# BL702 register map
Vendor: Bouffalo Lab; Series: WiFi BT; File version: 1.0
Registers are 32-bit, read-write, reset 0x0 unless marked. A register's access mark holds for its fields unless they carry their own. Offsets are from the block's base; [hi:lo] are bit positions; {n}, {i} and the like mark numbered series.

## CAM
Base 0x4000AD00
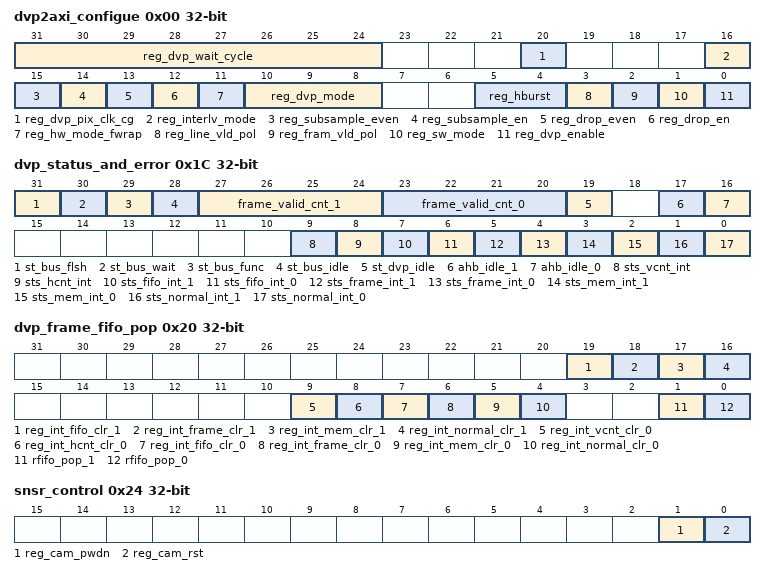
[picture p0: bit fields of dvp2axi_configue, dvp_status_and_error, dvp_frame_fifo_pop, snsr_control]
0x00 dvp2axi_configue
  [31:24] reg_dvp_wait_cycle, [20] reg_dvp_pix_clk_cg, [16] reg_interlv_mode, [15] reg_subsample_even, [14] reg_subsample_en, [13] reg_drop_even, [12] reg_drop_en, [11] reg_hw_mode_fwrap, [10:8] reg_dvp_mode, [5:4] reg_hburst, [3] reg_line_vld_pol, [2] reg_fram_vld_pol, [1] reg_sw_mode, [0] reg_dvp_enable
0x04 dvp2ahb_addr_start_0
  [31:0] reg_addr_start_0
0x08 dvp2ahb_mem_bcnt_0
  [31:0] reg_mem_burst_cnt_0
0x0C dvp2ahb_frame_bcnt_0
  [31:0] reg_frame_burst_cnt_0
0x10 dvp2ahb_addr_start_1
  [31:0] reg_addr_start_1
0x14 dvp2ahb_mem_bcnt_1
  [31:0] reg_mem_burst_cnt_1
0x18 dvp2ahb_frame_bcnt_1
  [31:0] reg_frame_burst_cnt_1
0x1C dvp_status_and_error
  [31] st_bus_flsh, [30] st_bus_wait, [29] st_bus_func, [28] st_bus_idle, [27:24] frame_valid_cnt_1, [23:20] frame_valid_cnt_0, [19] st_dvp_idle, [17] ahb_idle_1, [16] ahb_idle_0, [9] sts_vcnt_int, [8] sts_hcnt_int, [7] sts_fifo_int_1, [6] sts_fifo_int_0, [5] sts_frame_int_1, [4] sts_frame_int_0, [3] sts_mem_int_1, [2] sts_mem_int_0, [1] sts_normal_int_1, [0] sts_normal_int_0
0x20 dvp_frame_fifo_pop
  [19] reg_int_fifo_clr_1, [18] reg_int_frame_clr_1, [17] reg_int_mem_clr_1, [16] reg_int_normal_clr_1, [9] reg_int_vcnt_clr_0, [8] reg_int_hcnt_clr_0, [7] reg_int_fifo_clr_0, [6] reg_int_frame_clr_0, [5] reg_int_mem_clr_0, [4] reg_int_normal_clr_0, [1] rfifo_pop_1, [0] rfifo_pop_0
0x24 snsr_control
  [1] reg_cam_pwdn, [0] reg_cam_rst
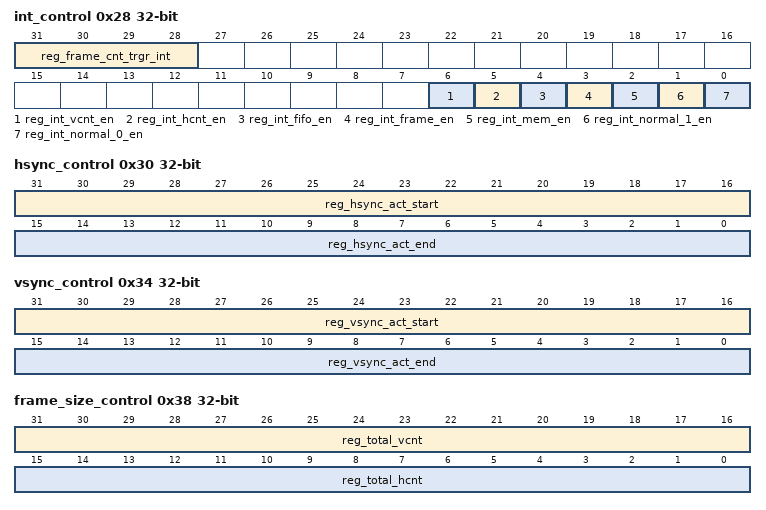
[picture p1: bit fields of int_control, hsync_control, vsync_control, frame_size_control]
0x28 int_control
  [31:28] reg_frame_cnt_trgr_int, [6] reg_int_vcnt_en, [5] reg_int_hcnt_en, [4] reg_int_fifo_en, [3] reg_int_frame_en, [2] reg_int_mem_en, [1] reg_int_normal_1_en, [0] reg_int_normal_0_en
0x30 hsync_control
  [31:16] reg_hsync_act_start, [15:0] reg_hsync_act_end
0x34 vsync_control
  [31:16] reg_vsync_act_start, [15:0] reg_vsync_act_end
0x38 frame_size_control
  [31:16] reg_total_vcnt, [15:0] reg_total_hcnt
{0x40+8i} frame_start_addr0_{i} (i=0..7)
  [31:0] frame_start_addr_0_{i}
{0x44+8i} frame_byte_cnt0_{i} (i=0..7)
  [31:0] frame_byte_cnt_0_{i}
{0x80+8i} frame_start_addr1_{i} (i=0..7)
  [31:0] frame_start_addr_1_{i}
{0x84+8i} frame_byte_cnt1_{i} (i=0..7)
  [31:0] frame_byte_cnt_1_{i}
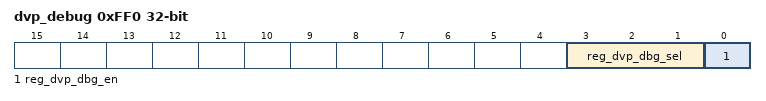
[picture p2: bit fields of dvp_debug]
0xFF0 dvp_debug
  [3:1] reg_dvp_dbg_sel, [0] reg_dvp_dbg_en
0xFFC dvp_dummy_reg

## DMA — DMA control
Base 0x40007000
0x00 DMA_IntStatus
  [7:0] IntStatus
0x04 DMA_IntTCStatus
  [7:0] IntTCStatus
0x08 DMA_IntTCClear
  [7:0] IntTCClear
0x0C DMA_IntErrorStatus
  [7:0] IntErrorStatus
0x10 DMA_IntErrClr
  [7:0] IntErrClr
0x14 DMA_RawIntTCStatus
  [7:0] RawIntTCStatus
0x18 DMA_RawIntErrorStatus
  [7:0] RawIntErrorStatus
0x1C DMA_EnbldChns
  [7:0] EnabledChannels
0x20 DMA_SoftBReq
0x24 DMA_SoftSReq
0x28 DMA_SoftLBReq
0x2C DMA_SoftLSReq
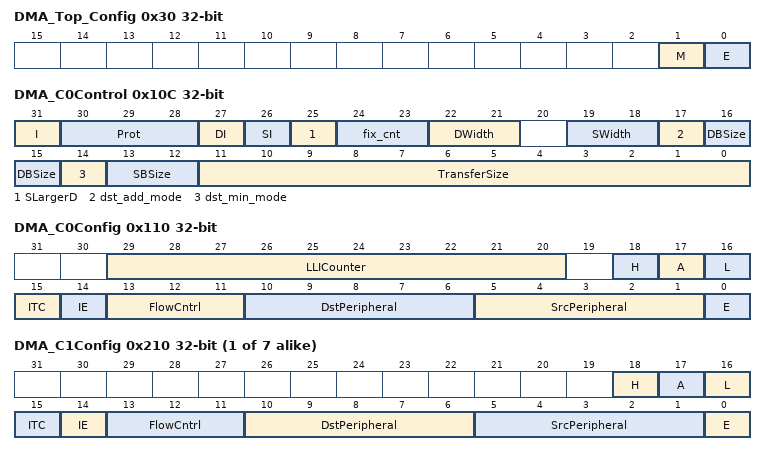
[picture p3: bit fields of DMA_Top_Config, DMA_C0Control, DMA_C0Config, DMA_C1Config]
0x30 DMA_Top_Config
  [1] M, [0] E
0x34 DMA_Sync
{0x100+0x100*i} DMA_C{i}SrcAddr (i=0..7)
  [31:0] SrcAddr
{0x104+0x100*i} DMA_C{i}DstAddr (i=0..7)
  [31:0] DstAddr
0x108 DMA_C0LLI
  [31:0] LLI
0x10C DMA_C0Control
  [31] I, [30:28] Prot, [27] DI, [26] SI, [25] SLargerD, [24:23] fix_cnt, [22:21] DWidth, [19:18] SWidth, [17] dst_add_mode, [16:15] DBSize, [14] dst_min_mode, [13:12] SBSize, [11:0] TransferSize
0x110 DMA_C0Config
  [29:20] LLICounter, [18] H, [17] A, [16] L, [15] ITC, [14] IE, [13:11] FlowCntrl, [10:6] DstPeripheral, [5:1] SrcPeripheral, [0] E
{0x108+0x100*i} DMA_C{i}LLI (i=1..7)
  [31:2] LLI
{0x10C+0x100*i} DMA_C{i}Control (i=1..7)
  [31] I, [30:28] Prot, [27] DI, [26] SI, [24:23] fix_cnt, [23:21] DWidth, [20:18] SWidth, [17] dst_add_mode, [16:15] DBSize, [14] dst_min_mode, [13:12] SBSize, [11:0] TransferSize
{0x110+0x100*i} DMA_C{i}Config (i=1..7)
  [18] H, [17] A, [16] L, [15] ITC, [14] IE, [13:11] FlowCntrl, [10:6] DstPeripheral, [5:1] SrcPeripheral, [0] E
